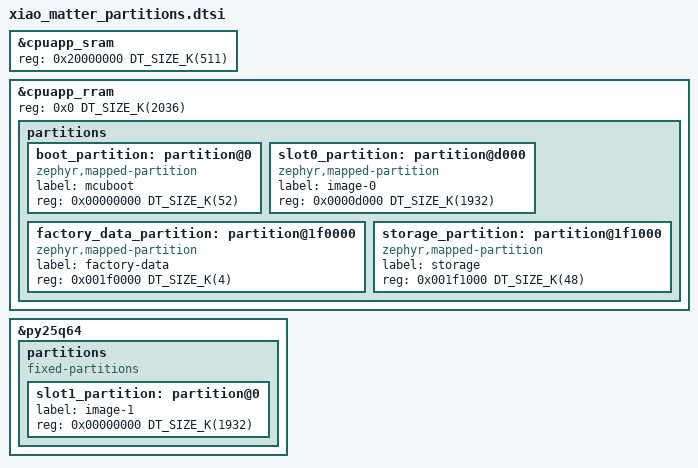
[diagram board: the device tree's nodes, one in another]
/*
 * Matter partition layout for XIAO nRF54LM20A, modelled on NCS
 * nrf/dts/samples/matter/nrf54lm20_cpuapp_partitions.dtsi, with the DFU
 * secondary slot in the on-board PY25Q64 external flash (Seeed wiki).
 */

&cpuapp_sram {
	reg = <0x20000000 DT_SIZE_K(511)>;
	ranges = <0x0 0x20000000 DT_SIZE_K(511)>;
};

&cpuapp_rram {
	reg = <0x0 DT_SIZE_K(2036)>;

	/delete-node/ partitions;

	partitions {
		ranges;
		#address-cells = <1>;
		#size-cells = <1>;

		boot_partition: partition@0 {
			compatible = "zephyr,mapped-partition";
			label = "mcuboot";
			reg = <0x00000000 DT_SIZE_K(52)>;
		};

		slot0_partition: partition@d000 {
			compatible = "zephyr,mapped-partition";
			label = "image-0";
			reg = <0x0000d000 DT_SIZE_K(1932)>;
		};

		factory_data_partition: partition@1f0000 {
			compatible = "zephyr,mapped-partition";
			label = "factory-data";
			reg = <0x001f0000 DT_SIZE_K(4)>;
		};

		storage_partition: partition@1f1000 {
			compatible = "zephyr,mapped-partition";
			label = "storage";
			reg = <0x001f1000 DT_SIZE_K(48)>;
		};
	};
};

&py25q64 {
	status = "okay";

	partitions {
		compatible = "fixed-partitions";
		#address-cells = <1>;
		#size-cells = <1>;

		slot1_partition: partition@0 {
			label = "image-1";
			reg = <0x00000000 DT_SIZE_K(1932)>;
		};
	};
};
